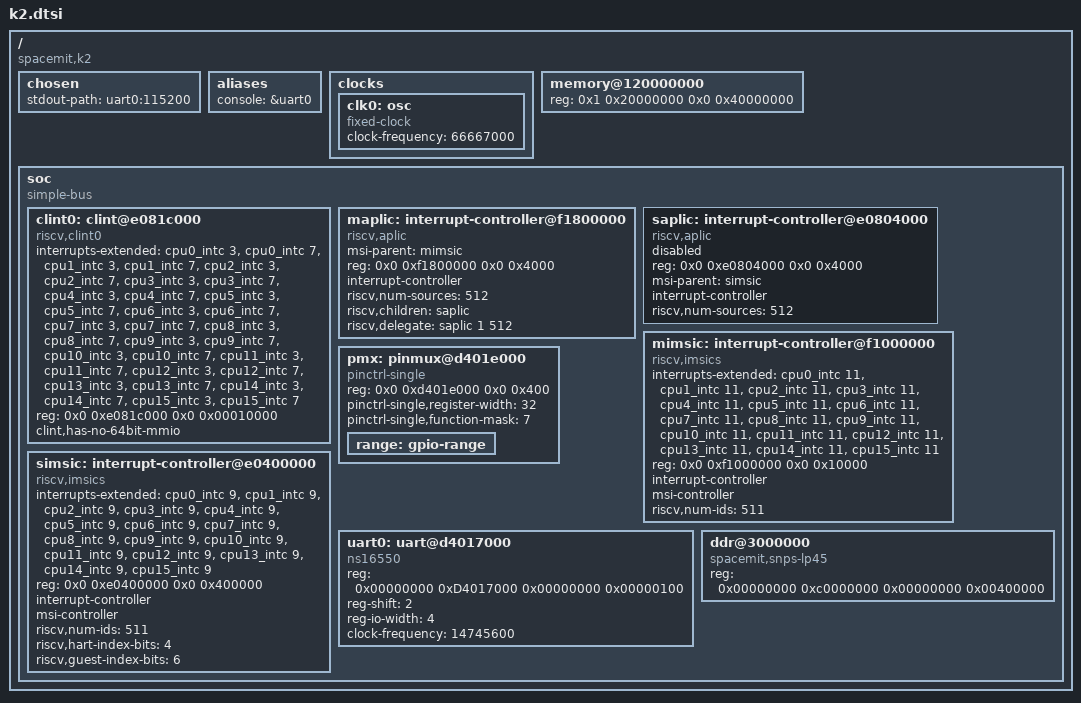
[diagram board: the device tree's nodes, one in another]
// SPDX-License-Identifier: GPL-2.0
/*
 * finch board's base device tree configure.
 *
 * Copyright (C) 2025 SPACEMIT Micro Limited
 */

/dts-v1/;

#include <config.h>
#include "k2-cpus.dtsi"

/ {
	#address-cells = <2>;
	#size-cells = <2>;
	compatible = "spacemit,k2";

	chosen {
		stdout-path = "uart0:115200";
	};

	aliases {
		console = &uart0;
	};

	clocks {
		clk0: osc {
			compatible = "fixed-clock";
			#clock-cells = <0>;
			clock-frequency = <66667000>;
		};
	};

	memory@120000000 {
		u-boot,dm-spl;
		device_type = "memory";
		reg = <0x1 0x20000000 0x0 0x40000000>;
	};

	soc {
		u-boot,dm-spl;
		#address-cells = <2>;
		#size-cells = <2>;
		compatible = "simple-bus";
		ranges;

		clint0: clint@e081c000 {
			compatible = "riscv,clint0";
			interrupts-extended = <&cpu0_intc  3 &cpu0_intc  7
				&cpu1_intc  3 &cpu1_intc  7
				&cpu2_intc  3 &cpu2_intc  7
				&cpu3_intc  3 &cpu3_intc  7
				&cpu4_intc  3 &cpu4_intc  7
				&cpu5_intc  3 &cpu5_intc  7
				&cpu6_intc  3 &cpu6_intc  7
				&cpu7_intc  3 &cpu7_intc  7
				&cpu8_intc  3 &cpu8_intc  7
				&cpu9_intc  3 &cpu9_intc  7
				&cpu10_intc  3 &cpu10_intc  7
				&cpu11_intc  3 &cpu11_intc  7
				&cpu12_intc  3 &cpu12_intc  7
				&cpu13_intc  3 &cpu13_intc  7
				&cpu14_intc  3 &cpu14_intc  7
				&cpu15_intc  3 &cpu15_intc  7
			>;
			reg = <0x0 0xe081c000 0x0 0x00010000>;
			clint,has-no-64bit-mmio;
		};

		maplic: interrupt-controller@f1800000 {
			compatible = "riscv,aplic";
			msi-parent = <&mimsic>;
			/*aplic config*/
			reg = <0x0 0xf1800000 0x0 0x4000>;
			interrupt-controller;
			#interrupt-cells = <2>;
			/*the number of wired interrupt sources*/
			riscv,num-sources = <512>;
			riscv,children = <&saplic>;
			/*M-mode delegate S-mode*/
			riscv,delegate = <&saplic 1 512>;
			status = "okay";
		};

		saplic: interrupt-controller@e0804000 {
			compatible = "riscv,aplic";
			/*aplic config*/
			reg = <0x0 0xe0804000 0x0 0x4000>;
			msi-parent = <&simsic>;
			#interrupt-cells = <2>;
			interrupt-controller;
			/*the number of wired interrupt sources*/
			riscv,num-sources = <512>;
			status = "disabled";
		};

		mimsic: interrupt-controller@f1000000 {
			compatible = "riscv,imsics";
			interrupts-extended = <&cpu0_intc 11 &cpu1_intc 11
					&cpu2_intc 11 &cpu3_intc 11
					&cpu4_intc 11 &cpu5_intc 11
					&cpu6_intc 11 &cpu7_intc 11
					&cpu8_intc 11 &cpu9_intc 11
					&cpu10_intc 11 &cpu11_intc 11
					&cpu12_intc 11 &cpu13_intc 11
					&cpu14_intc 11 &cpu15_intc 11>;

                        reg = <0x0 0xf1000000 0x0 0x10000>;

			interrupt-controller;
			#interrupt-cells = <0>;
			#msi-cells = <0>;
			msi-controller;
			/* Number of interrupt identities:512*/
			riscv,num-ids = <511>;
			status = "okay";
		};

		simsic: interrupt-controller@e0400000 {
			compatible = "riscv,imsics";

			interrupts-extended = <&cpu0_intc 9 &cpu1_intc 9
				&cpu2_intc 9 &cpu3_intc 9
				&cpu4_intc 9 &cpu5_intc 9
				&cpu6_intc 9 &cpu7_intc 9
				&cpu8_intc 9 &cpu9_intc 9
				&cpu10_intc 9 &cpu11_intc 9
				&cpu12_intc 9 &cpu13_intc 9
				&cpu14_intc 9 &cpu15_intc 9>;

                        reg = <0x0 0xe0400000 0x0 0x400000>;

			interrupt-controller;
			#interrupt-cells = <0>;
			#msi-cells = <0>;
			msi-controller;
			/* Number of interrupt identities:512*/
			riscv,num-ids = <511>;
			/* Number of HART index bits:16 */
			riscv,hart-index-bits = <4>;
			/* Number of guest index bits:7 */
			riscv,guest-index-bits = <6>;
			status = "okay";
		};

		pmx: pinmux@d401e000 {
			compatible = "pinctrl-single";
			reg = <0x0 0xd401e000 0x0 0x400>;
			#address-cells = <1>;
			#size-cells = <1>;
			#pinctrl-cells = <1>;
			#gpio-range-cells = <3>;
			ranges;
			pinctrl-single,register-width = <32>;
			pinctrl-single,function-mask = <7>;

			range: gpio-range {
			#pinctrl-single,gpio-range-cells = <3>;
			};
		};

		uart0: uart@d4017000 {
			u-boot,dm-spl;
			compatible = "ns16550";
			reg = <0x00000000 0xD4017000 0x00000000 0x00000100>;
			reg-shift = <2>;
			reg-io-width = <4>;
			clock-frequency = <14745600>;
		};

		ddr@3000000 {
			u-boot,dm-spl;
			compatible = "spacemit,snps-lp45";
			reg = <0x00000000 0xc0000000 0x00000000 0x00400000>;
			status = "okay";
		};
	};

};

